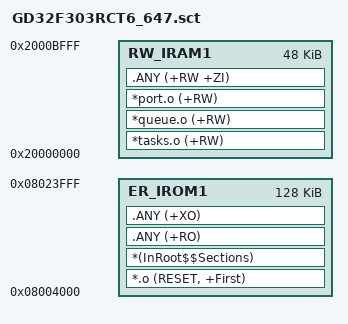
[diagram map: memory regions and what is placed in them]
; *************************************************************
; *** Scatter-Loading Description File generated by uVision ***
; *************************************************************

LR_IROM1 0x08004000 0x00020000 {
  ER_IROM1 0x08004000 0x00020000 {
    *.o (RESET, +First)
    *(InRoot$$Sections)
    .ANY (+RO)
    .ANY (+XO)
  }
  RW_IRAM1 0x20000000 0x0000C000 {
    ; 优先放置 FreeRTOS 的关键数据
    *tasks.o (+RW)
    *queue.o (+RW)
    *port.o (+RW)
    
    .ANY (+RW +ZI)
  }
}
